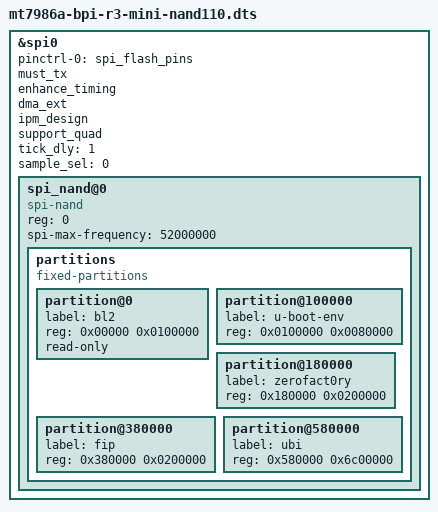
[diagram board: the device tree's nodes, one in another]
// SPDX-License-Identifier: GPL-2.0
/*
 * Copyright (c) 2021 MediaTek Inc.
 * Author: Sam Shih <sam.shih@mediatek.com>
 */

/dts-v1/;
#include "mt7986a-bpi-r3-mini.dts"
#include <dt-bindings/gpio/gpio.h>


&spi0 {
	#address-cells = <1>;
	#size-cells = <0>;
	pinctrl-names = "default";
	pinctrl-0 = <&spi_flash_pins>;
	status = "okay";
	must_tx;
	enhance_timing;
	dma_ext;
	ipm_design;
	support_quad;
	tick_dly = <1>;
	sample_sel = <0>;

	spi_nand@0 {
		compatible = "spi-nand";
		reg = <0>;
		spi-max-frequency = <52000000>;

		partitions {
			compatible = "fixed-partitions";
			#address-cells = <1>;
			#size-cells = <1>;

			partition@0 {
				label = "bl2";
				reg = <0x00000 0x0100000>;
				read-only;
			};

			partition@100000 {
				label = "u-boot-env";
				reg = <0x0100000 0x0080000>;
			};

			partition@180000 {
				label = "zerofact0ry";
				reg = <0x180000 0x0200000>;
			};

			partition@380000 {
				label = "fip";
				reg = <0x380000 0x0200000>;
			};

			partition@580000 {
				label = "ubi";
				reg = <0x580000 0x6c00000>;
			};
		};
	};

};
